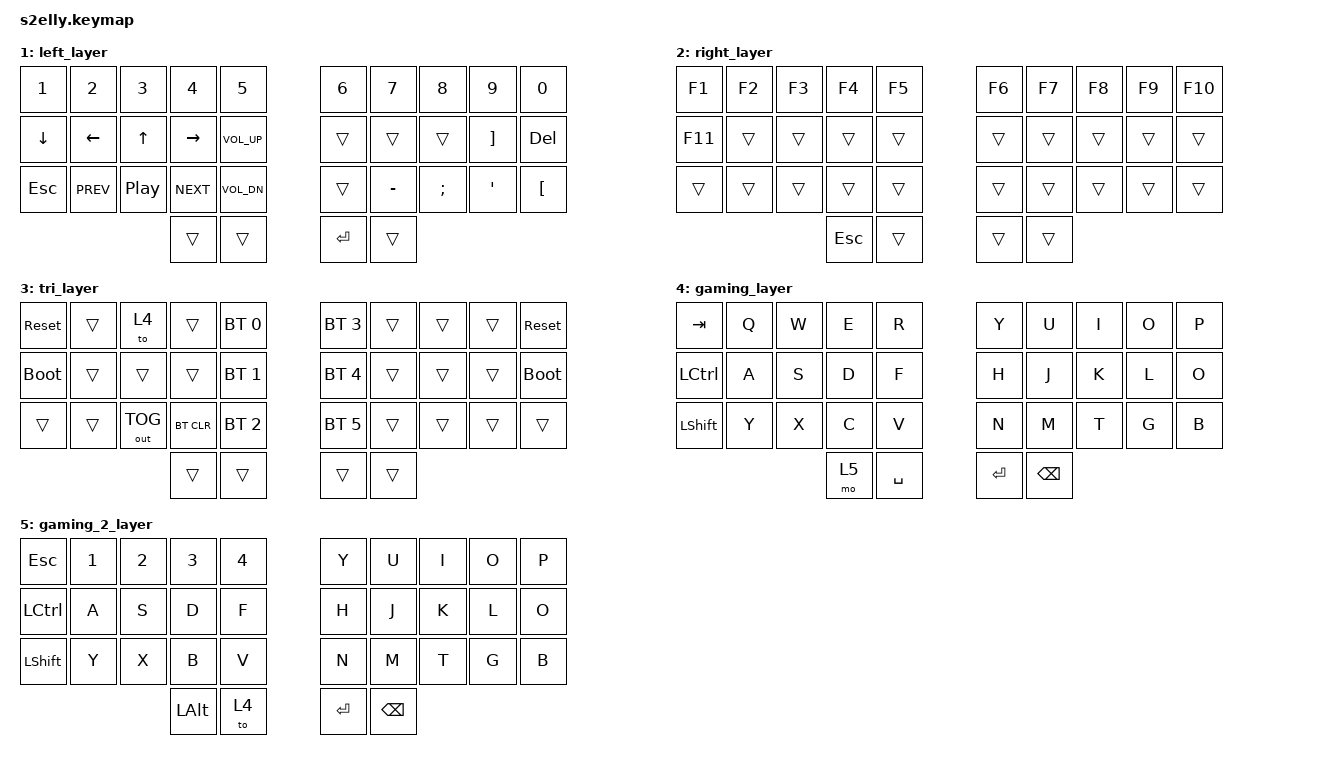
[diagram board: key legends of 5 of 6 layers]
// Copyright (c) 2022 The ZMK Contributors
// SPDX-License-Identifier: MIT

#include <behaviors.dtsi>
#include <dt-bindings/zmk/keys.h>
#include <dt-bindings/zmk/bt.h>
#include <dt-bindings/zmk/outputs.h>

// Home row mods macro
#define HRML(k1,k2,k3,k4) &ht LCTRL k1  &ht LSHFT k2  &ht LALT k3  &ht LGUI k4
#define HRMR(k1,k2,k3,k4) &ht RGUI k1  &ht RALT k2  &ht RSHIFT k3  &ht RCTRL k4

/ {
    behaviors {
        ht: hold_tap {
            compatible = "zmk,behavior-hold-tap";
            #binding-cells = <2>;
            flavor = "tap-preferred";
            tapping-term-ms = <220>;
            quick-tap-ms = <150>;
            global-quick-tap;
            bindings = <&kp>, <&kp>;
        };
    };


    conditional_layers {
        compatible = "zmk,conditional-layers";
        tri_layer {
            if-layers = <1 2>;
            then-layer = <3>;
        };
    };

    keymap {
        compatible = "zmk,keymap";
        default_layer {
            bindings = <
        //╭──────────┬──────────┬──────────┬──────────┬──────────╮   ╭──────────┬──────────┬──────────┬──────────┬──────────╮
        //│  Q       │  W       │  E       │  R       │  T       │   │  Z       │  U       │  I       │  O       │  P       │
             &kp Q       &kp W      &kp E      &kp R      &kp T         &kp Y      &kp U      &kp I      &kp O      &kp P
        //├──────────┼──────────┼──────────┼──────────┼──────────┤   ├──────────┼──────────┼──────────┼──────────┼──────────┤
        //│  A       │  S       │  D       │  F       │  G       │   │  H       │  J       │  K       │  L       │  : ;     │
            HRML(A,        S,         D,         F)     &kp G          &kp H      HRMR(J,        K,         L,        SEMI)
        //├──────────┼──────────┼──────────┼──────────┼──────────┤   ├──────────┼──────────┼──────────┼──────────┼──────────┤
        //│  Y       │  X       │  C       │  V       │  B       │   │  N       │  M       │  , ;     │  . :     │  - _     │
             &kp Z       &kp X      &kp C      &kp V      &kp B        &kp N      &kp M      &kp COMMA  &kp DOT    &kp FSLH
        //╰──────────┴──────────┴──────────┼──────────┼──────────┤   ├──────────┼──────────┼──────────┴──────────┴──────────╯
        //                                 │ Left Tab │  Space   │   │  ENTER   │Right BKSP│
                                            &lt 1 TAB   &kp SPACE      &kp ENTER &lt 2 BSPC
        //                                 ╰──────────┴──────────╯   ╰──────────┴──────────╯
            >;
        };

        left_layer {
            bindings = <
        //╭──────────┬──────────┬──────────┬──────────┬──────────╮   ╭──────────┬──────────┬──────────┬──────────┬──────────╮
        //│  1  !    │  2  "    │  3  §    │  4  $    │  5  %    │   │  6  &    │  7  /  { │  8  (  [ │  9  )  ] │  0  =  } │
            &kp N1     &kp N2      &kp N3     &kp N4     &kp N5         &kp N6     &kp N7     &kp N8     &kp N9     &kp N0      
        //├──────────┼──────────┼──────────┼──────────┼──────────┤   ├──────────┼──────────┼──────────┼──────────┼──────────┤
        //│Arrow_Down│ Arrow_L  │ Arrow_Up │  Arrow_R │          │   │          │          │          │ +  *  ~  │  DEL     │
            &kp DOWN   &kp LEFT   &kp UP     &kp RIGHT  &kp C_VOL_UP   &trans     &trans     &trans     &kp RBKT   &kp DEL    
        //├──────────┼──────────┼──────────┼──────────┼──────────┤   ├──────────┼──────────┼──────────┼──────────┼──────────┤
        //│   ESC    │          │          │          │          │   │    # '   │  ß ? \   │    Ö     │    Ä     │    Ü     │
            &kp ESC    &kp C_PREV &kp C_PP   &kp C_NEXT  &kp C_VOL_DN  &trans   &kp MINUS    &kp SEMI   &kp SQT    &kp LBKT   
        //╰──────────┴──────────┴──────────┼──────────┼──────────┤   ├──────────┼──────────┼──────────┴──────────┴──────────╯
        //                                 │          │          │   │  ENTER   │          │
                                             &trans     &trans        &kp ENTER   &trans
        //                                 ╰──────────┴──────────╯   ╰──────────┴──────────╯
            >;
        };
        
        right_layer {
            bindings = <
        //╭──────────┬──────────┬──────────┬──────────┬──────────╮   ╭──────────┬──────────┬──────────┬──────────┬──────────╮
        //│          │          │          │          │          │   │          │          │          │          │          │
            &kp F1     &kp F2     &kp F3     &kp F4     &kp F5          &kp F6     &kp F7     &kp F8     &kp F9     &kp F10
        //├──────────┼──────────┼──────────┼──────────┼──────────┤   ├──────────┼──────────┼──────────┼──────────┼──────────┤
        //│          │          │          │          │          │   │          │          │          │          │          │
            &kp F11    &trans     &trans     &trans     &trans          &trans     &trans     &trans     &trans     &trans    
        //├──────────┼──────────┼──────────┼──────────┼──────────┤   ├──────────┼──────────┼──────────┼──────────┼──────────┤
        //│          │          │          │          │          │   │          │          │          │          │          │
            &trans     &trans     &trans     &trans     &trans          &trans     &trans     &trans     &trans     &trans   
        //╰──────────┴──────────┴──────────┼──────────┼──────────┤   ├──────────┼──────────┼──────────┴──────────┴──────────╯
        //                                 │          │          │   │          │          │
                                             &kp ESC    &trans          &trans     &trans
        //                                 ╰──────────┴──────────╯   ╰──────────┴──────────╯
            >;
        };

        tri_layer {
            bindings = <
        //╭──────────┬──────────┬──────────┬──────────┬──────────╮   ╭──────────┬──────────┬──────────┬──────────┬──────────╮
        //│ RESET    │          │          │          │PROFILE 0 │   │PROFILE 3 │          │          │          │  RESET   │
           &sys_reset  &trans     &to 4      &trans    &bt BT_SEL 0  &bt BT_SEL 3 &trans     &trans     &trans    &sys_reset
        //├──────────┼──────────┼──────────┼──────────┼──────────┤   ├──────────┼──────────┼──────────┼──────────┼──────────┤
        //│BOOTLOADER│          │          │          │PROFILE 1 │   │PROFILE 4 │          │          │          │BOOTLOADER│
          &bootloader  &trans     &trans     &trans    &bt BT_SEL 1  &bt BT_SEL 4 &trans     &trans     &trans    &bootloader
        //├──────────┼──────────┼──────────┼──────────┼──────────┤   ├──────────┼──────────┼──────────┼──────────┼──────────┤
        //│          │          │          │ CLEAR BT │PROFILE 2 │   │PROFILE 5 │          │          │          │          │
            &trans     &trans &out OUT_TOG &bt BT_CLR  &bt BT_SEL 2  &bt BT_SEL 5 &trans     &trans     &trans     &trans
        //╰──────────┴──────────┴──────────┼──────────┼──────────┤   ├──────────┼──────────┼──────────┴──────────┴──────────╯
        //                                 │          │          │   │          │          │
                                             &trans     &trans         &trans     &trans
        //                                 ╰──────────┴──────────╯   ╰──────────┴──────────╯
            >;
        };

        gaming_layer {
            bindings = <
        //╭──────────┬──────────┬──────────┬──────────┬──────────╮   ╭──────────┬──────────┬──────────┬──────────┬──────────╮
        //│          │          │          │          │          │   │          │          │          │          │          │
             &kp TAB   &kp Q      &kp W      &kp E      &kp R           &kp Y      &kp U      &kp I      &kp O      &kp P
        //├──────────┼──────────┼──────────┼──────────┼──────────┤   ├──────────┼──────────┼──────────┼──────────┼──────────┤
        //│          │          │          │          │          │   │          │          │          │          │          │
            &kp LCTRL  &kp A      &kp S      &kp D      &kp F           &kp H      &kp J      &kp K      &kp L      &kp O
        //├──────────┼──────────┼──────────┼──────────┼──────────┤   ├──────────┼──────────┼──────────┼──────────┼──────────┤
        //│          │          │          │          │          │   │          │          │          │          │          │
            &kp LSHIFT &kp Y      &kp X      &kp C      &kp V           &kp N      &kp M      &kp T      &kp G      &kp B
        //╰──────────┴──────────┴──────────┼──────────┼──────────┤   ├──────────┼──────────┼──────────┴──────────┴──────────╯
        //                                 │          │          │   │          │          │
                                             &mo 5      &kp SPACE      &kp ENTER   &kp BSPC
        //                                 ╰──────────┴──────────╯   ╰──────────┴──────────╯
            >;
        };
        gaming_2_layer {
            bindings = <
        //╭──────────┬──────────┬──────────┬──────────┬──────────╮   ╭──────────┬──────────┬──────────┬──────────┬──────────╮
        //│          │          │          │          │          │   │          │          │          │          │          │
             &kp ESC   &kp N1     &kp N2     &kp N3     &kp N4         &kp Y      &kp U      &kp I      &kp O      &kp P
        //├──────────┼──────────┼──────────┼──────────┼──────────┤   ├──────────┼──────────┼──────────┼──────────┼──────────┤
        //│          │          │          │          │          │   │          │          │          │          │          │
            &kp LCTRL  &kp A      &kp S      &kp D      &kp F           &kp H      &kp J      &kp K      &kp L      &kp O
        //├──────────┼──────────┼──────────┼──────────┼──────────┤   ├──────────┼──────────┼──────────┼──────────┼──────────┤
        //│          │          │          │          │          │   │          │          │          │          │          │
            &kp LSHIFT &kp Y      &kp X      &kp B      &kp V           &kp N      &kp M      &kp T      &kp G      &kp B
        //╰──────────┴──────────┴──────────┼──────────┼──────────┤   ├──────────┼──────────┼──────────┴──────────┴──────────╯
        //                                 │          │          │   │          │          │
                                             &kp LALT   &to 4           &kp ENTER  &kp BSPC
        //                                 ╰──────────┴──────────╯   ╰──────────┴──────────╯
            >;
        };
    };
};
